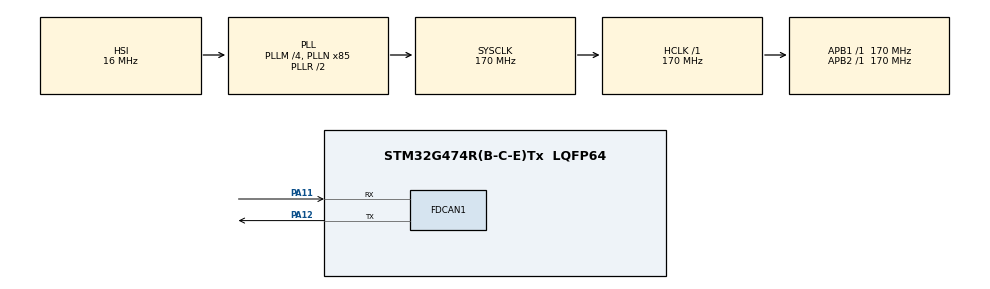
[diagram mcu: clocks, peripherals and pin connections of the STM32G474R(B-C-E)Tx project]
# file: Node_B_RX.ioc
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FDCAN1.AutoRetransmission=ENABLE
FDCAN1.NominalPrescaler=20
FDCAN1.NominalSyncJumpWidth=2
FDCAN1.NominalTimeSeg1=14
FDCAN1.NominalTimeSeg2=2
FDCAN1.StdFiltersNbr=1
Mcu.Family=STM32G4
Mcu.Name=STM32G474R(B-C-E)Tx
Mcu.Package=LQFP64
NVIC.FDCAN1_IT0_IRQn=true\:0\:0\:false\:false\:true\:true\:true\:true
NVIC.PriorityGroup=NVIC_PRIORITYGROUP_4
PA11.Mode=FDCAN_Activate
PA11.Signal=FDCAN1_RX
PA12.Mode=FDCAN_Activate
PA12.Signal=FDCAN1_TX
ProjectManager.HeapSize=0x200
ProjectManager.StackSize=0x400
ProjectManager.TargetToolchain=STM32CubeIDE
RCC.ADC12Freq_Value=170000000
RCC.ADC345Freq_Value=170000000
RCC.AHBFreq_Value=170000000
RCC.APB1Freq_Value=170000000
RCC.APB1TimFreq_Value=170000000
RCC.APB2Freq_Value=170000000
RCC.APB2TimFreq_Value=170000000
RCC.CortexFreq_Value=170000000
RCC.EXTERNAL_CLOCK_VALUE=12288000
RCC.HCLKFreq_Value=170000000
RCC.HSE_VALUE=24000000
RCC.HSI48_VALUE=48000000
RCC.HSI_VALUE=16000000
RCC.LSE_VALUE=32768
RCC.PLLM=RCC_PLLM_DIV4
RCC.PLLN=85
RCC.RTCClockSelection=RCC_RTCCLKSOURCE_LSE
RCC.SYSCLKFreq_VALUE=170000000
RCC.SYSCLKSource=RCC_SYSCLKSOURCE_PLLCLK
RCC.USBFreq_Value=170000000
RCC.VCOOutputFreq_Value=340000000
VP_SYS_VS_DBSignals.Mode=DisableDeadBatterySignals
board=NUCLEO-G474RE

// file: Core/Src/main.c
/* USER CODE BEGIN Header */
/**
  ******************************************************************************
  * @file           : main.c
  * @brief          : Main program body
  ******************************************************************************
  * @attention
  *
  * Copyright (c) 2026 STMicroelectronics.
  * All rights reserved.
  *
  * This software is licensed under terms that can be found in the LICENSE file
  * in the root directory of this software component.
  * If no LICENSE file comes with this software, it is provided AS-IS.
  *
  ******************************************************************************
  */
/* USER CODE END Header */
#include "main.h"

 FDCAN_HandleTypeDef hfdcan1;

/* USER CODE BEGIN PV */
 FDCAN_RxHeaderTypeDef RxHeader;
 uint8_t RxData[8];
 HAL_StatusTypeDef rxStatus;
 uint8_t messageReceived = 0;
 volatile uint32_t rxCount = 0;
 HAL_StatusTypeDef filterStatus;
 HAL_StatusTypeDef startStatus;
 uint32_t fdcanError;
 FDCAN_ProtocolStatusTypeDef protocolStatus;
/* USER CODE END PV */

void SystemClock_Config(void);
static void MX_GPIO_Init(void);
static void MX_FDCAN1_Init(void);

int main(void)
{

  /* MCU Configuration--------------------------------------------------------*/

  /* Reset of all peripherals, Initializes the Flash interface and the Systick. */
  HAL_Init();

  /* Configure the system clock */
  SystemClock_Config();

  /* Initialize all configured peripherals */
  MX_GPIO_Init();
  MX_FDCAN1_Init();
  /* USER CODE BEGIN 2 */
  FDCAN_FilterTypeDef sFilterConfig;

  sFilterConfig.IdType = FDCAN_STANDARD_ID;
  sFilterConfig.FilterIndex = 0;
  sFilterConfig.FilterType = FDCAN_FILTER_MASK;
  sFilterConfig.FilterConfig = FDCAN_FILTER_TO_RXFIFO0;

  sFilterConfig.FilterID1 = 0x000;
  sFilterConfig.FilterID2 = 0x000;

  filterStatus = HAL_FDCAN_ConfigFilter(&hfdcan1, &sFilterConfig);

  startStatus = HAL_FDCAN_Start(&hfdcan1);

  /* USER CODE END 2 */

  /* Infinite loop */
  while (1)
  {

    /* USER CODE BEGIN 3 */
	  rxStatus = HAL_FDCAN_GetRxMessage( &hfdcan1, FDCAN_RX_FIFO0, &RxHeader, RxData);
	  if(rxStatus == HAL_OK)
	  {
	      messageReceived = 1;
	      rxCount++;
	  }
	  fdcanError = HAL_FDCAN_GetError(&hfdcan1);

	  HAL_FDCAN_GetProtocolStatus(&hfdcan1, &protocolStatus);
  }
  /* USER CODE END 3 */
}

void SystemClock_Config(void)
{
  RCC_OscInitTypeDef RCC_OscInitStruct = {0};
  RCC_ClkInitTypeDef RCC_ClkInitStruct = {0};

  /** Configure the main internal regulator output voltage
  */
  HAL_PWREx_ControlVoltageScaling(PWR_REGULATOR_VOLTAGE_SCALE1_BOOST);

  /** Initializes the RCC Oscillators according to the specified parameters
  * in the RCC_OscInitTypeDef structure.
  */
  RCC_OscInitStruct.OscillatorType = RCC_OSCILLATORTYPE_HSI;
  RCC_OscInitStruct.HSIState = RCC_HSI_ON;
  RCC_OscInitStruct.HSICalibrationValue = RCC_HSICALIBRATION_DEFAULT;
  RCC_OscInitStruct.PLL.PLLState = RCC_PLL_ON;
  RCC_OscInitStruct.PLL.PLLSource = RCC_PLLSOURCE_HSI;
  RCC_OscInitStruct.PLL.PLLM = RCC_PLLM_DIV4;
  RCC_OscInitStruct.PLL.PLLN = 85;
  RCC_OscInitStruct.PLL.PLLP = RCC_PLLP_DIV2;
  RCC_OscInitStruct.PLL.PLLQ = RCC_PLLQ_DIV2;
  RCC_OscInitStruct.PLL.PLLR = RCC_PLLR_DIV2;
  if (HAL_RCC_OscConfig(&RCC_OscInitStruct) != HAL_OK)
  {
    Error_Handler();
  }

  /** Initializes the CPU, AHB and APB buses clocks
  */
  RCC_ClkInitStruct.ClockType = RCC_CLOCKTYPE_HCLK|RCC_CLOCKTYPE_SYSCLK
                              |RCC_CLOCKTYPE_PCLK1|RCC_CLOCKTYPE_PCLK2;
  RCC_ClkInitStruct.SYSCLKSource = RCC_SYSCLKSOURCE_PLLCLK;
  RCC_ClkInitStruct.AHBCLKDivider = RCC_SYSCLK_DIV1;
  RCC_ClkInitStruct.APB1CLKDivider = RCC_HCLK_DIV1;
  RCC_ClkInitStruct.APB2CLKDivider = RCC_HCLK_DIV1;

  if (HAL_RCC_ClockConfig(&RCC_ClkInitStruct, FLASH_LATENCY_4) != HAL_OK)
  {
    Error_Handler();
  }
}

static void MX_FDCAN1_Init(void)
{

  hfdcan1.Instance = FDCAN1;
  hfdcan1.Init.ClockDivider = FDCAN_CLOCK_DIV1;
  hfdcan1.Init.FrameFormat = FDCAN_FRAME_CLASSIC;
  hfdcan1.Init.Mode = FDCAN_MODE_NORMAL;
  hfdcan1.Init.AutoRetransmission = ENABLE;
  hfdcan1.Init.TransmitPause = DISABLE;
  hfdcan1.Init.ProtocolException = DISABLE;
  hfdcan1.Init.NominalPrescaler = 20;
  hfdcan1.Init.NominalSyncJumpWidth = 2;
  hfdcan1.Init.NominalTimeSeg1 = 14;
  hfdcan1.Init.NominalTimeSeg2 = 2;
  hfdcan1.Init.DataPrescaler = 1;
  hfdcan1.Init.DataSyncJumpWidth = 1;
  hfdcan1.Init.DataTimeSeg1 = 1;
  hfdcan1.Init.DataTimeSeg2 = 1;
  hfdcan1.Init.StdFiltersNbr = 1;
  hfdcan1.Init.ExtFiltersNbr = 0;
  hfdcan1.Init.TxFifoQueueMode = FDCAN_TX_FIFO_OPERATION;
  if (HAL_FDCAN_Init(&hfdcan1) != HAL_OK)
  {
    Error_Handler();
  }

}

static void MX_GPIO_Init(void)
{

  /* GPIO Ports Clock Enable */
  __HAL_RCC_GPIOA_CLK_ENABLE();

}

void Error_Handler(void)
{
  __disable_irq();
  while (1)
  {
  }
}
